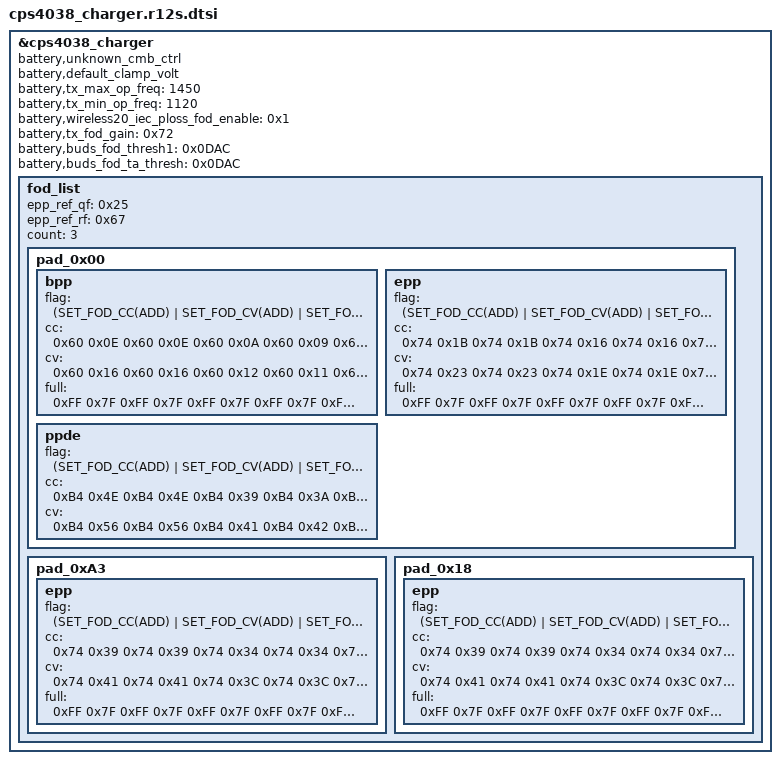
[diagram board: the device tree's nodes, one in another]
#include <dt-bindings/battery/sec-battery.h>

&cps4038_charger {
	battery,unknown_cmb_ctrl;
	battery,default_clamp_volt;
	battery,tx_max_op_freq = <1450>;
	battery,tx_min_op_freq = <1120>;
	battery,wireless20_iec_ploss_fod_enable = <0x1>;
	battery,tx_fod_gain = <0x72>;
	battery,buds_fod_thresh1 = <0x0DAC>;
	battery,buds_fod_ta_thresh = <0x0DAC>;

	fod_list {
		epp_ref_qf = <0x25>;
		epp_ref_rf = <0x67>;

		count = <3>;

		pad_0x00 { /* DEFAULT */
			bpp { /* DEFAULT OP MODE */
				flag = <(SET_FOD_CC(ADD) | SET_FOD_CV(ADD) | SET_FOD_FULL(ADD))>;
				cc = <0x60 0x0E 0x60 0x0E 0x60 0x0A 0x60 0x09 0x60 0x09 0x60 0x08 0x60 0x08 0x60 0x08 0x60 0x08 0x60 0x08>;
				cv = <0x60 0x16 0x60 0x16 0x60 0x12 0x60 0x11 0x60 0x11 0x60 0x10 0x60 0x10 0x60 0x10 0x60 0x10 0x60 0x10>;
				full = <0xFF 0x7F 0xFF 0x7F 0xFF 0x7F 0xFF 0x7F 0xFF 0x7F 0xFF 0x7F 0xFF 0x7F 0xFF 0x7F 0xFF 0x7F 0xFF 0x7F>;
			};

			epp {
				flag = <(SET_FOD_CC(ADD) | SET_FOD_CV(ADD) | SET_FOD_FULL(ADD))>;
				cc = <0x74 0x1B 0x74 0x1B 0x74 0x16 0x74 0x16 0x74 0x17 0x74 0x17 0x6A 0x18 0x6A 0x18 0x6A 0x18 0x0E 0x02>;
				cv = <0x74 0x23 0x74 0x23 0x74 0x1E 0x74 0x1E 0x74 0x1F 0x74 0x1F 0x6A 0x20 0x6A 0x20 0x6A 0x20 0x0E 0x02>;
				full = <0xFF 0x7F 0xFF 0x7F 0xFF 0x7F 0xFF 0x7F 0xFF 0x7F 0xFF 0x7F 0xFF 0x7F 0xFF 0x7F 0xFF 0x7F 0x0E 0x02>;
			};

			ppde {
				flag = <(SET_FOD_CC(ADD) | SET_FOD_CV(ADD) | SET_FOD_FULL(USE_DEF_OP))>;
				cc = <0xB4 0x4E 0xB4 0x4E 0xB4 0x39 0xB4 0x3A 0xB4 0x3B 0xB4 0x3B 0xB4 0x3A 0xB4 0x36 0xB4 0x36 0xB4 0x36>;
				cv = <0xB4 0x56 0xB4 0x56 0xB4 0x41 0xB4 0x42 0xB4 0x43 0xB4 0x43 0xB4 0x42 0xB4 0x3E 0xB4 0x3E 0xB4 0x3E>;
			};
		};

		pad_0xA3 { /* p2400 */
			epp {
				flag = <(SET_FOD_CC(ADD) | SET_FOD_CV(ADD) | SET_FOD_FULL(ADD))>;
				cc = <0x74 0x39 0x74 0x39 0x74 0x34 0x74 0x34 0x74 0x35 0x74 0x35 0x6A 0x38 0x6A 0x38 0x6A 0x38 0x0E 0x2E>;
				cv = <0x74 0x41 0x74 0x41 0x74 0x3C 0x74 0x3C 0x74 0x3D 0x74 0x3D 0x6A 0x40 0x6A 0x40 0x6A 0x40 0x6A 0x40>;
				full = <0xFF 0x7F 0xFF 0x7F 0xFF 0x7F 0xFF 0x7F 0xFF 0x7F 0xFF 0x7F 0xFF 0x7F 0xFF 0x7F 0xFF 0x7F 0xFF 0x7F>;
			};
		};

		pad_0x18 { /* p2400 */
			epp {
				flag = <(SET_FOD_CC(ADD) | SET_FOD_CV(ADD) | SET_FOD_FULL(ADD))>;
				cc = <0x74 0x39 0x74 0x39 0x74 0x34 0x74 0x34 0x74 0x35 0x74 0x35 0x6A 0x38 0x6A 0x38 0x6A 0x38 0x0E 0x2E>;
				cv = <0x74 0x41 0x74 0x41 0x74 0x3C 0x74 0x3C 0x74 0x3D 0x74 0x3D 0x6A 0x40 0x6A 0x40 0x6A 0x40 0x6A 0x40>;
				full = <0xFF 0x7F 0xFF 0x7F 0xFF 0x7F 0xFF 0x7F 0xFF 0x7F 0xFF 0x7F 0xFF 0x7F 0xFF 0x7F 0xFF 0x7F 0xFF 0x7F>;
			};
		};
	};
};
